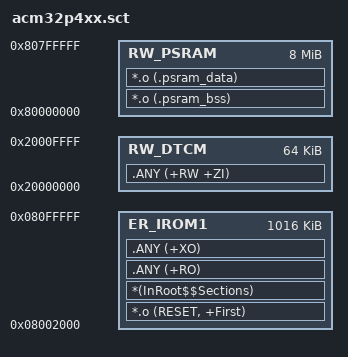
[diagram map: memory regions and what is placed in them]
; *************************************************************
; *** ACM32P4XX — DTCM + SRAM + PSRAM                   ***
; *************************************************************
; DTCM  0x20000000-0x2000FFFF  64KB   default RW/ZI + stack
; SRAM  0x20010000-0x2001FFFF  64KB   ETH DMA buffers (runtime)
; PSRAM 0x80000000-0x80800000  8MB    .psram_bss / .psram_data
; *************************************************************

LR_IROM1 0x08002000 0x000FE000 {
  ER_IROM1 0x08002000 0x000FE000 {
   *.o (RESET, +First)
   *(InRoot$$Sections)
   .ANY (+RO)
   .ANY (+XO)
  }
  RW_DTCM 0x20000000 0x00010000 {
   .ANY (+RW +ZI)
  }
  RW_PSRAM 0x80000000 0x00800000 {
   *.o (.psram_bss)
   *.o (.psram_data)
  }
}
